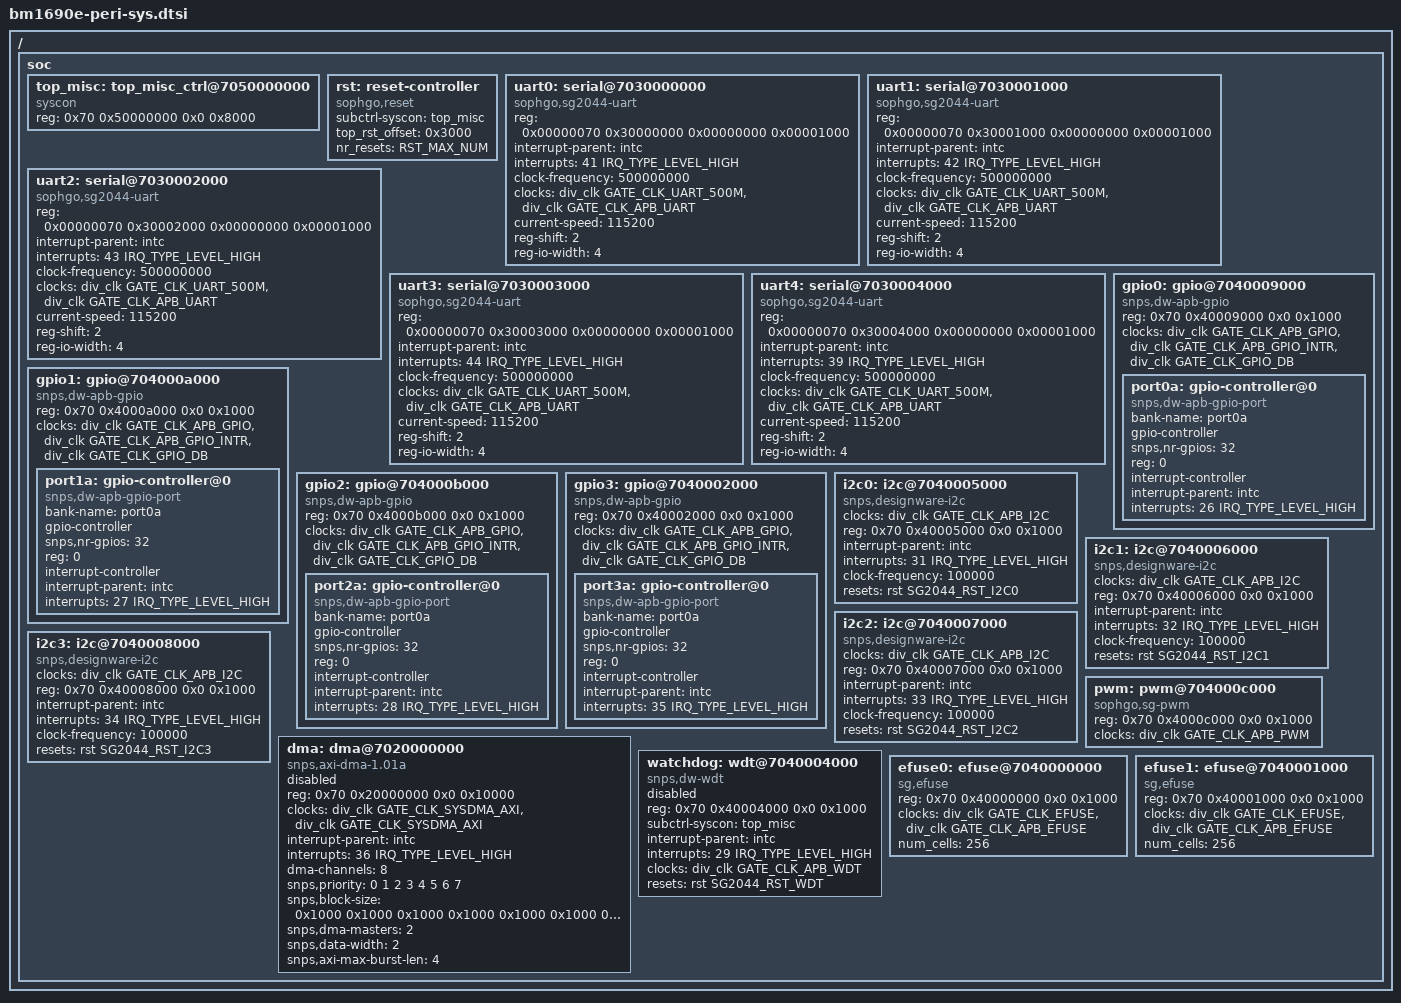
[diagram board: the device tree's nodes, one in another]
// SPDX-License-Identifier: (GPL-2.0 OR MIT)
/*
 * Copyright (C) 2022 Sophgo Technology Inc. All rights reserved.
 */

/ {
	soc {
		top_misc: top_misc_ctrl@7050000000 {
			compatible = "syscon";
			reg = <0x70 0x50000000 0x0 0x8000>;
		};

		rst: reset-controller {
			#reset-cells = <1>;
			compatible = "sophgo,reset";
			subctrl-syscon = <&top_misc>;
			top_rst_offset = <0x3000>;
			nr_resets = <RST_MAX_NUM>;
		};

		uart0: serial@7030000000 {
			compatible = "sophgo,sg2044-uart", "snps,dw-apb-uart";
			reg = <0x00000070 0x30000000 0x00000000 0x00001000>;
			interrupt-parent = <&intc>;
			interrupts = <41 IRQ_TYPE_LEVEL_HIGH>;
			clock-frequency = <500000000>;
			clocks = <&div_clk GATE_CLK_UART_500M>,
				<&div_clk GATE_CLK_APB_UART>;
			clock-names = "baudclk", "apb_pclk";
			current-speed = <115200>;
			reg-shift = <2>;
			reg-io-width = <4>;
		};

		uart1: serial@7030001000 {
			compatible = "sophgo,sg2044-uart", "snps,dw-apb-uart";
			reg = <0x00000070 0x30001000 0x00000000 0x00001000>;
			interrupt-parent = <&intc>;
			interrupts = <42 IRQ_TYPE_LEVEL_HIGH>;
			clock-frequency = <500000000>;
			clocks = <&div_clk GATE_CLK_UART_500M>,
				<&div_clk GATE_CLK_APB_UART>;
			clock-names = "baudclk", "apb_pclk";
			current-speed = <115200>;
			reg-shift = <2>;
			reg-io-width = <4>;
		};

		uart2: serial@7030002000 {
			compatible = "sophgo,sg2044-uart", "snps,dw-apb-uart";
			reg = <0x00000070 0x30002000 0x00000000 0x00001000>;
			interrupt-parent = <&intc>;
			interrupts = <43 IRQ_TYPE_LEVEL_HIGH>;
			clock-frequency = <500000000>;
			clocks = <&div_clk GATE_CLK_UART_500M>,
				<&div_clk GATE_CLK_APB_UART>;
			clock-names = "baudclk", "apb_pclk";
			current-speed = <115200>;
			reg-shift = <2>;
			reg-io-width = <4>;
		};

		uart3: serial@7030003000 {
			compatible = "sophgo,sg2044-uart", "snps,dw-apb-uart";
			reg = <0x00000070 0x30003000 0x00000000 0x00001000>;
			interrupt-parent = <&intc>;
			interrupts = <44 IRQ_TYPE_LEVEL_HIGH>;
			clock-frequency = <500000000>;
			clocks = <&div_clk GATE_CLK_UART_500M>,
				<&div_clk GATE_CLK_APB_UART>;
			clock-names = "baudclk", "apb_pclk";
			current-speed = <115200>;
			reg-shift = <2>;
			reg-io-width = <4>;
		};

        uart4: serial@7030004000 {
			compatible = "sophgo,sg2044-uart", "snps,dw-apb-uart";
			reg = <0x00000070 0x30004000 0x00000000 0x00001000>;
			interrupt-parent = <&intc>;
			interrupts = <39 IRQ_TYPE_LEVEL_HIGH>;
			clock-frequency = <500000000>;
			clocks = <&div_clk GATE_CLK_UART_500M>,
				<&div_clk GATE_CLK_APB_UART>;
			clock-names = "baudclk", "apb_pclk";
			current-speed = <115200>;
			reg-shift = <2>;
			reg-io-width = <4>;
		};

		gpio0: gpio@7040009000 {
			compatible = "snps,dw-apb-gpio";
			reg = <0x70 0x40009000 0x0 0x1000>;
			#address-cells = <1>;
			#size-cells = <0>;
			clocks = <&div_clk GATE_CLK_APB_GPIO>,
					<&div_clk GATE_CLK_APB_GPIO_INTR>,
					<&div_clk GATE_CLK_GPIO_DB>;
			clock-names = "base_clk", "intr_clk", "db_clk";

			port0a: gpio-controller@0 {
				compatible = "snps,dw-apb-gpio-port";
				bank-name = "port0a";
				gpio-controller;
				#gpio-cells = <2>;
				snps,nr-gpios = <32>;
				reg = <0>;
				interrupt-controller;
				#interrupt-cells = <2>;
				interrupt-parent = <&intc>;
				interrupts = <26 IRQ_TYPE_LEVEL_HIGH>;
			};
		};

		gpio1: gpio@704000a000 {
			compatible = "snps,dw-apb-gpio";
			reg = <0x70 0x4000a000 0x0 0x1000>;
			#address-cells = <1>;
			#size-cells = <0>;

			clocks = <&div_clk GATE_CLK_APB_GPIO>,
					<&div_clk GATE_CLK_APB_GPIO_INTR>,
					<&div_clk GATE_CLK_GPIO_DB>;
			clock-names = "base_clk", "intr_clk", "db_clk";

			port1a: gpio-controller@0 {
				compatible = "snps,dw-apb-gpio-port";
				bank-name = "port0a";
				gpio-controller;
				#gpio-cells = <2>;
				snps,nr-gpios = <32>;
				reg = <0>;
				interrupt-controller;
				#interrupt-cells = <2>;
				interrupt-parent = <&intc>;
				interrupts = <27 IRQ_TYPE_LEVEL_HIGH>;
			};
		};

		gpio2: gpio@704000b000 {
			compatible = "snps,dw-apb-gpio";
			reg = <0x70 0x4000b000 0x0 0x1000>;
			#address-cells = <1>;
			#size-cells = <0>;
			clocks = <&div_clk GATE_CLK_APB_GPIO>,
					<&div_clk GATE_CLK_APB_GPIO_INTR>,
					<&div_clk GATE_CLK_GPIO_DB>;
			clock-names = "base_clk", "intr_clk", "db_clk";

			port2a: gpio-controller@0 {
				compatible = "snps,dw-apb-gpio-port";
				bank-name = "port0a";
				gpio-controller;
				#gpio-cells = <2>;
				snps,nr-gpios = <32>;
				reg = <0>;
				interrupt-controller;
				#interrupt-cells = <2>;
				interrupt-parent = <&intc>;
				interrupts = <28 IRQ_TYPE_LEVEL_HIGH>;
			};
		};

		gpio3: gpio@7040002000 {
			compatible = "snps,dw-apb-gpio";
			reg = <0x70 0x40002000 0x0 0x1000>;
			#address-cells = <1>;
			#size-cells = <0>;
			clocks = <&div_clk GATE_CLK_APB_GPIO>,
					<&div_clk GATE_CLK_APB_GPIO_INTR>,
					<&div_clk GATE_CLK_GPIO_DB>;
			clock-names = "base_clk", "intr_clk", "db_clk";

			port3a: gpio-controller@0 {
				compatible = "snps,dw-apb-gpio-port";
				bank-name = "port0a";
				gpio-controller;
				#gpio-cells = <2>;
				snps,nr-gpios = <32>;
				reg = <0>;
				interrupt-controller;
				#interrupt-cells = <2>;
				interrupt-parent = <&intc>;
				interrupts = <35 IRQ_TYPE_LEVEL_HIGH>;
			};
		};

		i2c0: i2c@7040005000 {
			#address-cells = <1>;
			#size-cells = <0>;
			compatible = "snps,designware-i2c";
			clocks = <&div_clk GATE_CLK_APB_I2C>;
			clock-names = "clk_gate_apb_i2c";
			reg = <0x70 0x40005000 0x0 0x1000>;
			interrupt-parent = <&intc>;
			interrupts = <31 IRQ_TYPE_LEVEL_HIGH>;
			clock-frequency = <100000>;
			resets = <&rst SG2044_RST_I2C0>;
			reset-names = "i2c0";
		};

		i2c1: i2c@7040006000 {
			#address-cells = <1>;
			#size-cells = <0>;
			compatible = "snps,designware-i2c";
			clocks = <&div_clk GATE_CLK_APB_I2C>;
			clock-names = "clk_gate_apb_i2c";
			reg = <0x70 0x40006000 0x0 0x1000>;
			interrupt-parent = <&intc>;
			interrupts = <32 IRQ_TYPE_LEVEL_HIGH>;
			clock-frequency = <100000>;
			resets = <&rst SG2044_RST_I2C1>;
			reset-names = "i2c1";
		};

		i2c2: i2c@7040007000 {
			#address-cells = <1>;
			#size-cells = <0>;
			compatible = "snps,designware-i2c";
			clocks = <&div_clk GATE_CLK_APB_I2C>;
			clock-names = "clk_gate_apb_i2c";
			reg = <0x70 0x40007000 0x0 0x1000>;
			interrupt-parent = <&intc>;
			interrupts = <33 IRQ_TYPE_LEVEL_HIGH>;
			clock-frequency = <100000>;
			resets = <&rst SG2044_RST_I2C2>;
			reset-names = "i2c2";
		};

		i2c3: i2c@7040008000 {
			#address-cells = <1>;
			#size-cells = <0>;
			compatible = "snps,designware-i2c";
			clocks = <&div_clk GATE_CLK_APB_I2C>;
			clock-names = "clk_gate_apb_i2c";
			reg = <0x70 0x40008000 0x0 0x1000>;
			interrupt-parent = <&intc>;
			interrupts = <34 IRQ_TYPE_LEVEL_HIGH>;
			clock-frequency = <100000>;
			resets = <&rst SG2044_RST_I2C3>;
			reset-names = "i2c3";
		};

		pwm: pwm@704000c000 {
			compatible = "sophgo,sg-pwm";
			reg = <0x70 0x4000c000 0x0 0x1000>;
			clocks = <&div_clk GATE_CLK_APB_PWM>;
			#pwm-cells = <2>;
		};

		dma: dma@7020000000 {
			compatible = "snps,axi-dma-1.01a";
			reg = <0x70 0x20000000 0x0 0x10000>;
			clock-names = "core-clk", "cfgr-clk";
			clocks = <&div_clk GATE_CLK_SYSDMA_AXI>,
				 <&div_clk GATE_CLK_SYSDMA_AXI>;
			interrupt-parent = <&intc>;
			interrupts = <36 IRQ_TYPE_LEVEL_HIGH>;
			dma-channels = <8>;
			#dma-cells = <1>;
			snps,priority = <0 1 2 3 4 5 6 7>;
			snps,block-size = <0x1000 0x1000 0x1000 0x1000
					   0x1000 0x1000 0x1000 0x1000>;
			snps,dma-masters = <2>;
			snps,data-width = <2>;
			snps,axi-max-burst-len = <4>;
			status = "disable";
		};

		watchdog: wdt@7040004000 {
			compatible = "snps,dw-wdt";
			reg = <0x70 0x40004000 0x0 0x1000>;
			subctrl-syscon = <&top_misc>;
			interrupt-parent = <&intc>;
			interrupts = <29 IRQ_TYPE_LEVEL_HIGH>;
			clocks = <&div_clk GATE_CLK_APB_WDT>;
			resets = <&rst SG2044_RST_WDT>;
			status = "disable";
		};

		efuse0: efuse@7040000000 {
			compatible = "sg,efuse";
			reg = <0x70 0x40000000 0x0 0x1000>;
			clock-names = "base_clk", "apb_clk";
			clocks = <&div_clk GATE_CLK_EFUSE>,
				 <&div_clk GATE_CLK_APB_EFUSE>;
			num_cells = <256>;
		};

		efuse1: efuse@7040001000 {
			compatible = "sg,efuse";
			reg = <0x70 0x40001000 0x0 0x1000>;
			clock-names = "base_clk", "apb_clk";
			clocks = <&div_clk GATE_CLK_EFUSE>,
				 <&div_clk GATE_CLK_APB_EFUSE>;
			num_cells = <256>;
		};
	};
};
